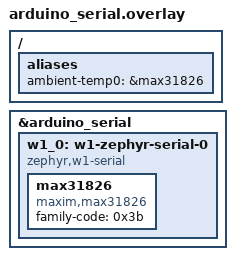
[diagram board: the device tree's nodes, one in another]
/*
 * Copyright (c) 2022 Thomas Stranger
 * Copyright (c) 2026 Foss Analytical A/S
 *
 * SPDX-License-Identifier: Apache-2.0
 */

/*
 * Example configuration of a MAX31826 device on an Arduino serial bus.
 * Requires external circuit to provide an open-drain interface.
 */

&arduino_serial {
	status = "okay";

	w1_0: w1-zephyr-serial-0 {
		compatible = "zephyr,w1-serial";
		#address-cells = <1>;
		#size-cells = <0>;
		status = "okay";

		max31826: max31826 {
			compatible = "maxim,max31826";
			family-code = <0x3b>;
			status = "okay";
		};
	};
};

/ {
	aliases {
		ambient-temp0 = &max31826;
	};
};
